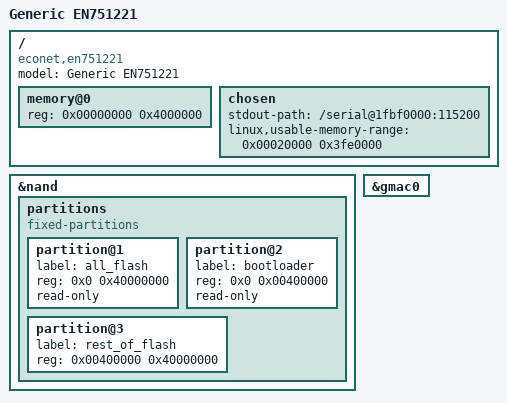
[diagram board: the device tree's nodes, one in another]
// SPDX-License-Identifier: GPL-2.0
/dts-v1/;

#include "en751221.dtsi"

/ {
	model = "Generic EN751221";
	compatible = "econet,en751221";

	memory@0 {
		// We hope at least 64MB will be available on every device
		device_type = "memory";
		reg = <0x00000000 0x4000000>;
	};

	chosen {
		stdout-path = "/serial@1fbf0000:115200";
		linux,usable-memory-range = <0x00020000 0x3fe0000>;
	};
};

&nand {
	status = "okay";

	partitions {
		compatible = "fixed-partitions";
		#address-cells = <1>;
		#size-cells = <1>;

		partition@1 {
			// We don't know how big the flash is
			// Put 1GB and let it truncate
			label = "all_flash";
			reg = <0x0 0x40000000>;
			read-only;
		};

		partition@2 {
			// We don't know how big the bootloader
			// is, but when we're doing testing, lets
			// make sure nobody touches anything below 4MB
			label = "bootloader";
			reg = <0x0 0x00400000>;
			read-only;
		};

		partition@3 {
			label = "rest_of_flash";
			reg = <0x00400000 0x40000000>;
		};
	};
};

&gmac0 {
	status = "okay";
};
